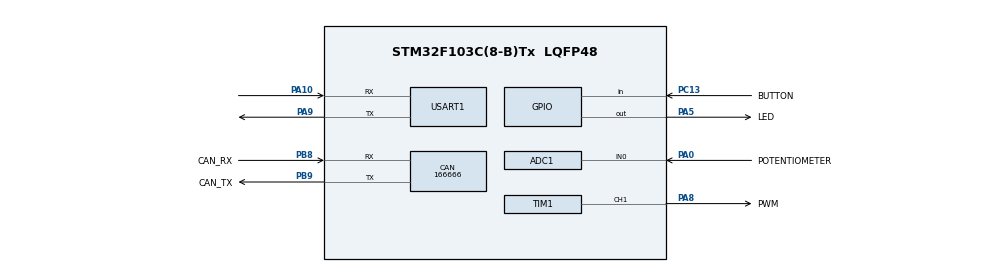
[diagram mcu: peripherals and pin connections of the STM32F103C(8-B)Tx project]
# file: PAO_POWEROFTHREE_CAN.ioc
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ADC1.Channel-0\#ChannelRegularConversion=ADC_CHANNEL_0
ADC1.NbrOfConversionFlag=1
ADC1.Rank-0\#ChannelRegularConversion=1
ADC1.SamplingTime-0\#ChannelRegularConversion=ADC_SAMPLETIME_1CYCLE_5
ADC1.master=1
CAN.CalculateBaudRate=166666
CAN.CalculateTimeBit=6000
CAN.CalculateTimeQuantum=2000.0
CAN.TTCM=DISABLE
Mcu.Family=STM32F1
Mcu.Name=STM32F103C(8-B)Tx
Mcu.Package=LQFP48
NVIC.PriorityGroup=NVIC_PRIORITYGROUP_4
PA0-WKUP.GPIO_Label=POTENTIOMETER
PA0-WKUP.Signal=ADCx_IN0
PA10.Mode=Asynchronous
PA10.Signal=USART1_RX
PA13.Mode=Serial_Wire
PA13.Signal=SYS_JTMS-SWDIO
PA14.Mode=Serial_Wire
PA14.Signal=SYS_JTCK-SWCLK
PA5.GPIO_Label=LED
PA5.Signal=GPIO_Output
PA8.GPIO_Label=PWM
PA8.Signal=S_TIM1_CH1
PA9.Mode=Asynchronous
PA9.Signal=USART1_TX
PB8.GPIO_Label=CAN_RX
PB8.Mode=CAN_Activate
PB8.Signal=CAN_RX
PB9.GPIO_Label=CAN_TX
PB9.Mode=CAN_Activate
PB9.Signal=CAN_TX
PC13-TAMPER-RTC.GPIO_Label=BUTTON
PC13-TAMPER-RTC.GPIO_PuPd=GPIO_PULLUP
PC13-TAMPER-RTC.Signal=GPIO_Input
ProjectManager.HeapSize=0x200
ProjectManager.StackSize=0x400
ProjectManager.TargetToolchain=CMake
RCC.APB1Freq_Value=8000000
RCC.APB2Freq_Value=8000000
SH.ADCx_IN0.0=ADC1_IN0,IN0
SH.S_TIM1_CH1.0=TIM1_CH1,PWM Generation1 CH1
TIM1.Channel-PWM\ Generation1\ CH1=TIM_CHANNEL_1
USART1.VirtualMode=VM_ASYNC
board=custom

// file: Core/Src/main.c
/* USER CODE BEGIN Header */
/**
  ******************************************************************************
  * @file           : main.c
  * @brief          : Main program body
  ******************************************************************************
  * @attention
  *
  * Copyright (c) 2025 STMicroelectronics.
  * All rights reserved.
  *
  * This software is licensed under terms that can be found in the LICENSE file
  * in the root directory of this software component.
  * If no LICENSE file comes with this software, it is provided AS-IS.
  *
  ******************************************************************************
  */
/* USER CODE END Header */
#include "main.h"

ADC_HandleTypeDef hadc1;

CAN_HandleTypeDef hcan;

TIM_HandleTypeDef htim1;

UART_HandleTypeDef huart1;

/* USER CODE BEGIN PV */
// static uint8_t led_state = 0; // LED state on PA5: 0 = OFF, 1 = ON
// static uint32_t last_button_press = 0; // Debounce variable
// static uint16_t adc_value = 0; // ADC reading from potentiometer on PA0
static uint8_t led_state = 0; // LED state on PA5
static uint32_t last_button_press = 0; // Debounce variable
static uint16_t adc_value = 0; // ADC reading from PA0
static uint32_t last_pwm_value = 0; // Last PWM value for change detection
static uint16_t last_adc_value = 0; // Last ADC value for change detection

/* USER CODE END PV */

void SystemClock_Config(void);
static void MX_GPIO_Init(void);
static void MX_ADC1_Init(void);
static void MX_TIM1_Init(void);
static void MX_USART1_UART_Init(void);
static void MX_CAN_Init(void);
/* USER CODE BEGIN PFP */
void send_can_message(uint32_t id, uint8_t *data, uint8_t len);

/* USER CODE END PFP */

int main(void)
{

  /* MCU Configuration--------------------------------------------------------*/

  /* Reset of all peripherals, Initializes the Flash interface and the Systick. */
  HAL_Init();

  /* Configure the system clock */
  SystemClock_Config();

  /* Initialize all configured peripherals */
  MX_GPIO_Init();
  MX_ADC1_Init();
  MX_TIM1_Init();
  MX_USART1_UART_Init();
  MX_CAN_Init();
  /* USER CODE BEGIN 2 */
  HAL_TIM_PWM_Start(&htim1, TIM_CHANNEL_1); // Start PWM on PA8
  HAL_ADC_Start(&hadc1); // Start ADC on PA0
  if (HAL_CAN_Start(&hcan) != HAL_OK)
  {
    Error_Handler();
  }
  /* USER CODE END 2 */

  /* Infinite loop */
  /* USER CODE BEGIN WHILE */
  while (1)
{
    if (HAL_GPIO_ReadPin(BUTTON_GPIO_Port, BUTTON_Pin) == GPIO_PIN_RESET &&
            (HAL_GetTick() - last_button_press) > 200)
        {
            led_state ^= 1;
            last_button_press = HAL_GetTick();
            HAL_GPIO_WritePin(LED_GPIO_Port, LED_Pin,led_state ? GPIO_PIN_SET : GPIO_PIN_RESET);
            char debug[32];
            snprintf(debug, sizeof(debug), "Button: %d\r\n", led_state);
            HAL_UART_Transmit(&huart1, (uint8_t*)debug, strlen(debug), HAL_MAX_DELAY);

            uint8_t d = led_state;
            send_can_message(0x101, &d, 1);
        }

        if (HAL_ADC_PollForConversion(&hadc1, 10) == HAL_OK)
        {
            adc_value = HAL_ADC_GetValue(&hadc1);
            HAL_ADC_Start(&hadc1);

            uint32_t pwm = (adc_value * 1000) / 4095;
            __HAL_TIM_SET_COMPARE(&htim1, TIM_CHANNEL_1, pwm);

            if (abs((int)pwm - (int)last_pwm_value) > 10)
            {
                char dbg[48];
                snprintf(dbg, sizeof(dbg), "ADC:%u PWM:%lu\r\n", adc_value, pwm);
                HAL_UART_Transmit(&huart1, (uint8_t*)dbg, strlen(dbg), HAL_MAX_DELAY);

                uint8_t buf[4] = {
                    (uint8_t)(adc_value >> 8),
                    (uint8_t)(adc_value & 0xFF),
                    (uint8_t)(pwm >> 8),
                    (uint8_t)(pwm & 0xFF)
                };
                send_can_message(0x102, buf, 4);

                last_pwm_value = pwm;
            }
        }

        HAL_Delay(50);
    }
}
/**
  * @brief Send CAN message
  * @param id: CAN message ID
  * @param data: Pointer to data array
  * @param len: Length of data (1-8 bytes)
  * @retval None
  */
void send_can_message(uint32_t id, uint8_t *data, uint8_t len)
{
  CAN_TxHeaderTypeDef tx_header;
  uint32_t tx_mailbox;

  // Validate input parameters
  if (len < 1 || len > 8)
  {
    Error_Handler(); // Invalid length
    return;
  }

  // Configure transmit header
  tx_header.StdId = id;
  tx_header.ExtId = 0;
  tx_header.IDE = CAN_ID_STD;
  tx_header.RTR = CAN_RTR_DATA;
  tx_header.DLC = len;
  tx_header.TransmitGlobalTime = DISABLE;

  // Attempt to add message to transmit mailbox
  if (HAL_CAN_AddTxMessage(&hcan, &tx_header, data, &tx_mailbox) != HAL_OK)
  {
    #ifdef DEBUG
    HAL_UART_Transmit(&huart1, (uint8_t*)"CAN Tx Error\n", 12, HAL_MAX_DELAY);
    #endif
    Error_Handler();
  }
}
void SystemClock_Config(void)
{
  RCC_OscInitTypeDef RCC_OscInitStruct = {0};
  RCC_ClkInitTypeDef RCC_ClkInitStruct = {0};
  RCC_PeriphCLKInitTypeDef PeriphClkInit = {0};

  /** Initializes the RCC Oscillators according to the specified parameters
  * in the RCC_OscInitTypeDef structure.
  */
  RCC_OscInitStruct.OscillatorType = RCC_OSCILLATORTYPE_HSI;
  RCC_OscInitStruct.HSIState = RCC_HSI_ON;
  RCC_OscInitStruct.HSICalibrationValue = RCC_HSICALIBRATION_DEFAULT;
  RCC_OscInitStruct.PLL.PLLState = RCC_PLL_NONE;
  if (HAL_RCC_OscConfig(&RCC_OscInitStruct) != HAL_OK)
  {
    Error_Handler();
  }

  /** Initializes the CPU, AHB and APB buses clocks
  */
  RCC_ClkInitStruct.ClockType = RCC_CLOCKTYPE_HCLK|RCC_CLOCKTYPE_SYSCLK
                              |RCC_CLOCKTYPE_PCLK1|RCC_CLOCKTYPE_PCLK2;
  RCC_ClkInitStruct.SYSCLKSource = RCC_SYSCLKSOURCE_HSI;
  RCC_ClkInitStruct.AHBCLKDivider = RCC_SYSCLK_DIV1;
  RCC_ClkInitStruct.APB1CLKDivider = RCC_HCLK_DIV1;
  RCC_ClkInitStruct.APB2CLKDivider = RCC_HCLK_DIV1;

  if (HAL_RCC_ClockConfig(&RCC_ClkInitStruct, FLASH_LATENCY_0) != HAL_OK)
  {
    Error_Handler();
  }
  PeriphClkInit.PeriphClockSelection = RCC_PERIPHCLK_ADC;
  PeriphClkInit.AdcClockSelection = RCC_ADCPCLK2_DIV2;
  if (HAL_RCCEx_PeriphCLKConfig(&PeriphClkInit) != HAL_OK)
  {
    Error_Handler();
  }
}

static void MX_ADC1_Init(void)
{

  ADC_ChannelConfTypeDef sConfig = {0};

  /** Common config
  */
  hadc1.Instance = ADC1;
  hadc1.Init.ScanConvMode = ADC_SCAN_DISABLE;
  hadc1.Init.ContinuousConvMode = DISABLE;
  hadc1.Init.DiscontinuousConvMode = DISABLE;
  hadc1.Init.ExternalTrigConv = ADC_SOFTWARE_START;
  hadc1.Init.DataAlign = ADC_DATAALIGN_RIGHT;
  hadc1.Init.NbrOfConversion = 1;
  if (HAL_ADC_Init(&hadc1) != HAL_OK)
  {
    Error_Handler();
  }

  /** Configure Regular Channel
  */
  sConfig.Channel = ADC_CHANNEL_0;
  sConfig.Rank = ADC_REGULAR_RANK_1;
  sConfig.SamplingTime = ADC_SAMPLETIME_1CYCLE_5;
  if (HAL_ADC_ConfigChannel(&hadc1, &sConfig) != HAL_OK)
  {
    Error_Handler();
  }

}

static void MX_CAN_Init(void)
{

  hcan.Instance = CAN1;
  hcan.Init.Mode = CAN_MODE_NORMAL;
  hcan.Init.SyncJumpWidth = CAN_SJW_1TQ;
  hcan.Init.Prescaler = 8;
  hcan.Init.TimeSeg1 = CAN_BS1_6TQ;
  hcan.Init.TimeSeg2 = CAN_BS2_1TQ;
  hcan.Init.TimeTriggeredMode = DISABLE;
  hcan.Init.AutoBusOff = DISABLE;
  hcan.Init.AutoWakeUp = DISABLE;
  hcan.Init.AutoRetransmission = DISABLE;
  hcan.Init.ReceiveFifoLocked = DISABLE;
  hcan.Init.TransmitFifoPriority = DISABLE;
  if (HAL_CAN_Init(&hcan) != HAL_OK)
  {
    Error_Handler();
  }

}

static void MX_TIM1_Init(void)
{

  TIM_MasterConfigTypeDef sMasterConfig = {0};
  TIM_OC_InitTypeDef sConfigOC = {0};
  TIM_BreakDeadTimeConfigTypeDef sBreakDeadTimeConfig = {0};

  htim1.Instance = TIM1;
  htim1.Init.Prescaler = 83;
  htim1.Init.CounterMode = TIM_COUNTERMODE_UP;
  htim1.Init.Period = 1000;
  htim1.Init.ClockDivision = TIM_CLOCKDIVISION_DIV1;
  htim1.Init.RepetitionCounter = 0;
  htim1.Init.AutoReloadPreload = TIM_AUTORELOAD_PRELOAD_DISABLE;
  if (HAL_TIM_PWM_Init(&htim1) != HAL_OK)
  {
    Error_Handler();
  }
  sMasterConfig.MasterOutputTrigger = TIM_TRGO_RESET;
  sMasterConfig.MasterSlaveMode = TIM_MASTERSLAVEMODE_DISABLE;
  if (HAL_TIMEx_MasterConfigSynchronization(&htim1, &sMasterConfig) != HAL_OK)
  {
    Error_Handler();
  }
  sConfigOC.OCMode = TIM_OCMODE_PWM1;
  sConfigOC.Pulse = 0;
  sConfigOC.OCPolarity = TIM_OCPOLARITY_HIGH;
  sConfigOC.OCNPolarity = TIM_OCNPOLARITY_HIGH;
  sConfigOC.OCFastMode = TIM_OCFAST_DISABLE;
  sConfigOC.OCIdleState = TIM_OCIDLESTATE_RESET;
  sConfigOC.OCNIdleState = TIM_OCNIDLESTATE_RESET;
  if (HAL_TIM_PWM_ConfigChannel(&htim1, &sConfigOC, TIM_CHANNEL_1) != HAL_OK)
  {
    Error_Handler();
  }
  sBreakDeadTimeConfig.OffStateRunMode = TIM_OSSR_DISABLE;
  sBreakDeadTimeConfig.OffStateIDLEMode = TIM_OSSI_DISABLE;
  sBreakDeadTimeConfig.LockLevel = TIM_LOCKLEVEL_OFF;
  sBreakDeadTimeConfig.DeadTime = 0;
  sBreakDeadTimeConfig.BreakState = TIM_BREAK_DISABLE;
  sBreakDeadTimeConfig.BreakPolarity = TIM_BREAKPOLARITY_HIGH;
  sBreakDeadTimeConfig.AutomaticOutput = TIM_AUTOMATICOUTPUT_DISABLE;
  if (HAL_TIMEx_ConfigBreakDeadTime(&htim1, &sBreakDeadTimeConfig) != HAL_OK)
  {
    Error_Handler();
  }
  HAL_TIM_MspPostInit(&htim1);

}

static void MX_USART1_UART_Init(void)
{

  huart1.Instance = USART1;
  huart1.Init.BaudRate = 115200;
  huart1.Init.WordLength = UART_WORDLENGTH_8B;
  huart1.Init.StopBits = UART_STOPBITS_1;
  huart1.Init.Parity = UART_PARITY_NONE;
  huart1.Init.Mode = UART_MODE_TX_RX;
  huart1.Init.HwFlowCtl = UART_HWCONTROL_NONE;
  huart1.Init.OverSampling = UART_OVERSAMPLING_16;
  if (HAL_UART_Init(&huart1) != HAL_OK)
  {
    Error_Handler();
  }

}

static void MX_GPIO_Init(void)
{
  GPIO_InitTypeDef GPIO_InitStruct = {0};

  /* GPIO Ports Clock Enable */
  __HAL_RCC_GPIOC_CLK_ENABLE();
  __HAL_RCC_GPIOA_CLK_ENABLE();

  /*Configure GPIO pin Output Level */
  HAL_GPIO_WritePin(LED_GPIO_Port, LED_Pin, GPIO_PIN_RESET);

  /*Configure GPIO pin : BUTTON_Pin */
  GPIO_InitStruct.Pin = BUTTON_Pin;
  GPIO_InitStruct.Mode = GPIO_MODE_INPUT;
  GPIO_InitStruct.Pull = GPIO_PULLUP;
  HAL_GPIO_Init(BUTTON_GPIO_Port, &GPIO_InitStruct);

  /*Configure GPIO pin : LED_Pin */
  GPIO_InitStruct.Pin = LED_Pin;
  GPIO_InitStruct.Mode = GPIO_MODE_OUTPUT_PP;
  GPIO_InitStruct.Pull = GPIO_NOPULL;
  GPIO_InitStruct.Speed = GPIO_SPEED_FREQ_LOW;
  HAL_GPIO_Init(LED_GPIO_Port, &GPIO_InitStruct);

}

void Error_Handler(void)
{
  __disable_irq();
  while (1)
  {
  }
}
